# Montana register map
Vendor: ONSemiconductor; Series: Montana Series; File version: 1.0
CPU: CM33 r0p4, little endian, MPU, FPU, 3 interrupt priority bits
Registers are 32-bit, read-write, reset 0x0 unless marked. A register's access mark holds for its fields unless they carry their own. Offsets are from the block's base; [hi:lo] are bit positions; {n}, {i} and the like mark numbered series.

## NVIC — Nested Vector Interrupt Controller
Base 0xE000E100
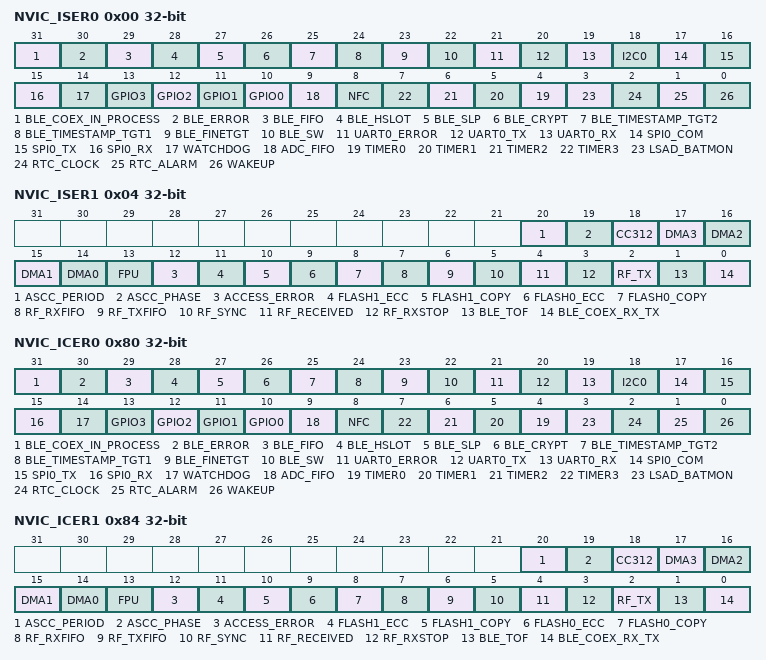
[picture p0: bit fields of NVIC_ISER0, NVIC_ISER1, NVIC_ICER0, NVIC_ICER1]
0x00 NVIC_ISER0 — NVIC External Interrupt Set Enable Register 0
  [31] BLE_COEX_IN_PROCESS — BLE_COEX_IN_PROCESS interrupt set enable
    1=NVIC_BLE_COEX_IN_PROCESS_INT_ENABLE (Enable the BLE_COEX_IN_PROCESS interrupt)
  [30] BLE_ERROR — BLE_ERROR interrupt set enable
    1=NVIC_BLE_ERROR_INT_ENABLE (Enable the BLE_ERROR interrupt)
  [29] BLE_FIFO — BLE_FIFO interrupt set enable
    1=NVIC_BLE_FIFO_INT_ENABLE (Enable the BLE_FIFO interrupt)
  [28] BLE_HSLOT — BLE_HSLOT interrupt set enable
    1=NVIC_BLE_HSLOT_INT_ENABLE (Enable the BLE_HSLOT interrupt)
  [27] BLE_SLP — BLE_SLP interrupt set enable
    1=NVIC_BLE_SLP_INT_ENABLE (Enable the BLE_SLP interrupt)
  [26] BLE_CRYPT — BLE_CRYPT interrupt set enable
    1=NVIC_BLE_CRYPT_INT_ENABLE (Enable the BLE_CRYPT interrupt)
  [25] BLE_TIMESTAMP_TGT2 — BLE_TIMESTAMP_TGT2 interrupt set enable
    1=NVIC_BLE_TIMESTAMP_TGT2_INT_ENABLE (Enable the BLE_TIMESTAMP_TGT2 interrupt)
  [24] BLE_TIMESTAMP_TGT1 — BLE_TIMESTAMP_TGT1 interrupt set enable
    1=NVIC_BLE_TIMESTAMP_TGT1_INT_ENABLE (Enable the BLE_TIMESTAMP_TGT1 interrupt)
  [23] BLE_FINETGT — BLE_FINETGT interrupt set enable
    1=NVIC_BLE_FINETGT_INT_ENABLE (Enable the BLE_FINETGT interrupt)
  [22] BLE_SW — BLE_SW interrupt set enable
    1=NVIC_BLE_SW_INT_ENABLE (Enable the BLE_SW interrupt)
  [21] UART0_ERROR — UART0_ERROR interrupt set enable
    1=NVIC_UART0_ERROR_INT_ENABLE (Enable the UART0_ERROR interrupt)
  [20] UART0_TX — UART0_TX interrupt set enable
    1=NVIC_UART0_TX_INT_ENABLE (Enable the UART0_TX interrupt)
  [19] UART0_RX — UART0_RX interrupt set enable
    1=NVIC_UART0_RX_INT_ENABLE (Enable the UART0_RX interrupt)
  [18] I2C0 — I2C0 interrupt set enable
    1=NVIC_I2C0_INT_ENABLE (Enable the I2C0 interrupt)
  [17] SPI0_COM — SPI0_COM interrupt set enable
    1=NVIC_SPI0_COM_INT_ENABLE (Enable the SPI0_COM interrupt)
  [16] SPI0_TX — SPI0_TX interrupt set enable
    1=NVIC_SPI0_TX_INT_ENABLE (Enable the SPI0_TX interrupt)
  [15] SPI0_RX — SPI0_RX interrupt set enable
    1=NVIC_SPI0_RX_INT_ENABLE (Enable the SPI0_RX interrupt)
  [14] WATCHDOG — WATCHDOG interrupt set enable
    1=NVIC_WATCHDOG_INT_ENABLE (Enable the WATCHDOG interrupt)
  [n+10] GPIO{n} (n=0..3) — GPIO{n} interrupt set enable
    1=NVIC_GPIO{n}_INT_ENABLE (Enable the GPIO{n} interrupt)
  [9] ADC_FIFO — ADC_FIFO interrupt set enable
    1=NVIC_ADC_FIFO_INT_ENABLE (Enable the ADC_FIFO interrupt)
  [8] NFC — NFC interrupt set enable
    1=NVIC_NFC_INT_ENABLE (Enable the NFC interrupt)
  [n+4] TIMER{n} (n=0..3) — TIMER{n} interrupt set enable
    1=NVIC_TIMER{n}_INT_ENABLE (Enable the TIMER{n} interrupt)
  [3] LSAD_BATMON — LSAD_BATMON interrupt set enable
    1=NVIC_LSAD_BATMON_INT_ENABLE (Enable the LSAD_BATMON interrupt)
  [2] RTC_CLOCK — RTC_CLOCK interrupt set enable
    1=NVIC_RTC_CLOCK_INT_ENABLE (Enable the RTC_CLOCK interrupt)
  [1] RTC_ALARM — RTC_ALARM interrupt set enable
    1=NVIC_RTC_ALARM_INT_ENABLE (Enable the RTC_ALARM interrupt)
  [0] WAKEUP — WAKEUP interrupt set enable
    1=NVIC_WAKEUP_INT_ENABLE (Enable the WAKEUP interrupt)
0x04 NVIC_ISER1 — NVIC External Interrupt Set Enable Register 1
  [20] ASCC_PERIOD — ASCC_PERIOD interrupt set enable
    1=NVIC_ASCC_PERIOD_INT_ENABLE (Enable the ASCC_PERIOD interrupt)
  [19] ASCC_PHASE — ASCC_PHASE interrupt set enable
    1=NVIC_ASCC_PHASE_INT_ENABLE (Enable the ASCC_PHASE interrupt)
  [18] CC312 — CC312 interrupt set enable
    1=NVIC_CC312_INT_ENABLE (Enable the CC312 interrupt)
  [n+14] DMA{n} (n=0..3) — DMA{n} interrupt set enable
    1=NVIC_DMA{n}_INT_ENABLE (Enable the DMA{n} interrupt)
  [13] FPU — FPU interrupt set enable
    1=NVIC_FPU_INT_ENABLE (Enable the FPU interrupt)
  [12] ACCESS_ERROR — ACCESS_ERROR interrupt set enable
    1=NVIC_ACCESS_ERROR_INT_ENABLE (Enable the ACCESS_ERROR interrupt)
  [11] FLASH1_ECC — FLASH1_ECC interrupt set enable
    1=NVIC_FLASH1_ECC_INT_ENABLE (Enable the FLASH1_ECC interrupt)
  [10] FLASH1_COPY — FLASH1_COPY interrupt set enable
    1=NVIC_FLASH1_COPY_INT_ENABLE (Enable the FLASH1_COPY interrupt)
  [9] FLASH0_ECC — FLASH0_ECC interrupt set enable
    1=NVIC_FLASH0_ECC_INT_ENABLE (Enable the FLASH0_ECC interrupt)
  [8] FLASH0_COPY — FLASH0_COPY interrupt set enable
    1=NVIC_FLASH0_COPY_INT_ENABLE (Enable the FLASH0_COPY interrupt)
  [7] RF_RXFIFO — RF_RXFIFO interrupt set enable
    1=NVIC_RF_RXFIFO_INT_ENABLE (Enable the RF_RXFIFO interrupt)
  [6] RF_TXFIFO — RF_TXFIFO interrupt set enable
    1=NVIC_RF_TXFIFO_INT_ENABLE (Enable the RF_TXFIFO interrupt)
  [5] RF_SYNC — RF_SYNC interrupt set enable
    1=NVIC_RF_SYNC_INT_ENABLE (Enable the RF_SYNC interrupt)
  [4] RF_RECEIVED — RF_RECEIVED interrupt set enable
    1=NVIC_RF_RECEIVED_INT_ENABLE (Enable the RF_RECEIVED interrupt)
  [3] RF_RXSTOP — RF_RXSTOP interrupt set enable
    1=NVIC_RF_RXSTOP_INT_ENABLE (Enable the RF_RXSTOP interrupt)
  [2] RF_TX — RF_TX interrupt set enable
    1=NVIC_RF_TX_INT_ENABLE (Enable the RF_TX interrupt)
  [1] BLE_TOF — BLE_TOF interrupt set enable
    1=NVIC_BLE_TOF_INT_ENABLE (Enable the BLE_TOF interrupt)
  [0] BLE_COEX_RX_TX — BLE_COEX_RX_TX interrupt set enable
    1=NVIC_BLE_COEX_RX_TX_INT_ENABLE (Enable the BLE_COEX_RX_TX interrupt)
0x80 NVIC_ICER0 — NVIC External Interrupt Clear Enable Register 0
  [31] BLE_COEX_IN_PROCESS — BLE_COEX_IN_PROCESS interrupt clear enable
    1=NVIC_BLE_COEX_IN_PROCESS_INT_DISABLE (Disable the BLE_COEX_IN_PROCESS interrupt)
  [30] BLE_ERROR — BLE_ERROR interrupt clear enable
    1=NVIC_BLE_ERROR_INT_DISABLE (Disable the BLE_ERROR interrupt)
  [29] BLE_FIFO — BLE_FIFO interrupt clear enable
    1=NVIC_BLE_FIFO_INT_DISABLE (Disable the BLE_FIFO interrupt)
  [28] BLE_HSLOT — BLE_HSLOT interrupt clear enable
    1=NVIC_BLE_HSLOT_INT_DISABLE (Disable the BLE_HSLOT interrupt)
  [27] BLE_SLP — BLE_SLP interrupt clear enable
    1=NVIC_BLE_SLP_INT_DISABLE (Disable the BLE_SLP interrupt)
  [26] BLE_CRYPT — BLE_CRYPT interrupt clear enable
    1=NVIC_BLE_CRYPT_INT_DISABLE (Disable the BLE_CRYPT interrupt)
  [25] BLE_TIMESTAMP_TGT2 — BLE_TIMESTAMP_TGT2 interrupt clear enable
    1=NVIC_BLE_TIMESTAMP_TGT2_INT_DISABLE (Disable the BLE_TIMESTAMP_TGT2 interrupt)
  [24] BLE_TIMESTAMP_TGT1 — BLE_TIMESTAMP_TGT1 interrupt clear enable
    1=NVIC_BLE_TIMESTAMP_TGT1_INT_DISABLE (Disable the BLE_TIMESTAMP_TGT1 interrupt)
  [23] BLE_FINETGT — BLE_FINETGT interrupt clear enable
    1=NVIC_BLE_FINETGT_INT_DISABLE (Disable the BLE_FINETGT interrupt)
  [22] BLE_SW — BLE_SW interrupt clear enable
    1=NVIC_BLE_SW_INT_DISABLE (Disable the BLE_SW interrupt)
  [21] UART0_ERROR — UART0_ERROR interrupt clear enable
    1=NVIC_UART0_ERROR_INT_DISABLE (Disable the UART0_ERROR interrupt)
  [20] UART0_TX — UART0_TX interrupt clear enable
    1=NVIC_UART0_TX_INT_DISABLE (Disable the UART0_TX interrupt)
  [19] UART0_RX — UART0_RX interrupt clear enable
    1=NVIC_UART0_RX_INT_DISABLE (Disable the UART0_RX interrupt)
  [18] I2C0 — I2C0 interrupt clear enable
    1=NVIC_I2C0_INT_DISABLE (Disable the I2C0 interrupt)
  [17] SPI0_COM — SPI0_COM interrupt clear enable
    1=NVIC_SPI0_COM_INT_DISABLE (Disable the SPI0_COM interrupt)
  [16] SPI0_TX — SPI0_TX interrupt clear enable
    1=NVIC_SPI0_TX_INT_DISABLE (Disable the SPI0_TX interrupt)
  [15] SPI0_RX — SPI0_RX interrupt clear enable
    1=NVIC_SPI0_RX_INT_DISABLE (Disable the SPI0_RX interrupt)
  [14] WATCHDOG — WATCHDOG interrupt clear enable
    1=NVIC_WATCHDOG_INT_DISABLE (Disable the WATCHDOG interrupt)
  [n+10] GPIO{n} (n=0..3) — GPIO{n} interrupt clear enable
    1=NVIC_GPIO{n}_INT_DISABLE (Disable the GPIO{n} interrupt)
  [9] ADC_FIFO — ADC_FIFO interrupt clear enable
    1=NVIC_ADC_FIFO_INT_DISABLE (Disable the ADC_FIFO interrupt)
  [8] NFC — NFC interrupt clear enable
    1=NVIC_NFC_INT_DISABLE (Disable the NFC interrupt)
  [n+4] TIMER{n} (n=0..3) — TIMER{n} interrupt clear enable
    1=NVIC_TIMER{n}_INT_DISABLE (Disable the TIMER{n} interrupt)
  [3] LSAD_BATMON — LSAD_BATMON interrupt clear enable
    1=NVIC_LSAD_BATMON_INT_DISABLE (Disable the LSAD_BATMON interrupt)
  [2] RTC_CLOCK — RTC_CLOCK interrupt clear enable
    1=NVIC_RTC_CLOCK_INT_DISABLE (Disable the RTC_CLOCK interrupt)
  [1] RTC_ALARM — RTC_ALARM interrupt clear enable
    1=NVIC_RTC_ALARM_INT_DISABLE (Disable the RTC_ALARM interrupt)
  [0] WAKEUP — WAKEUP interrupt clear enable
    1=NVIC_WAKEUP_INT_DISABLE (Disable the WAKEUP interrupt)
0x84 NVIC_ICER1 — NVIC External Interrupt Clear Enable Register 1
  [20] ASCC_PERIOD — ASCC_PERIOD interrupt clear enable
    1=NVIC_ASCC_PERIOD_INT_DISABLE (Disable the ASCC_PERIOD interrupt)
  [19] ASCC_PHASE — ASCC_PHASE interrupt clear enable
    1=NVIC_ASCC_PHASE_INT_DISABLE (Disable the ASCC_PHASE interrupt)
  [18] CC312 — CC312 interrupt clear enable
    1=NVIC_CC312_INT_DISABLE (Disable the CC312 interrupt)
  [n+14] DMA{n} (n=0..3) — DMA{n} interrupt clear enable
    1=NVIC_DMA{n}_INT_DISABLE (Disable the DMA{n} interrupt)
  [13] FPU — FPU interrupt clear enable
    1=NVIC_FPU_INT_DISABLE (Disable the FPU interrupt)
  [12] ACCESS_ERROR — ACCESS_ERROR interrupt clear enable
    1=NVIC_ACCESS_ERROR_INT_DISABLE (Disable the ACCESS_ERROR interrupt)
  [11] FLASH1_ECC — FLASH1_ECC interrupt clear enable
    1=NVIC_FLASH1_ECC_INT_DISABLE (Disable the FLASH1_ECC interrupt)
  [10] FLASH1_COPY — FLASH1_COPY interrupt clear enable
    1=NVIC_FLASH1_COPY_INT_DISABLE (Disable the FLASH1_COPY interrupt)
  [9] FLASH0_ECC — FLASH0_ECC interrupt clear enable
    1=NVIC_FLASH0_ECC_INT_DISABLE (Disable the FLASH0_ECC interrupt)
  [8] FLASH0_COPY — FLASH0_COPY interrupt clear enable
    1=NVIC_FLASH0_COPY_INT_DISABLE (Disable the FLASH0_COPY interrupt)
  [7] RF_RXFIFO — RF_RXFIFO interrupt clear enable
    1=NVIC_RF_RXFIFO_INT_DISABLE (Disable the RF_RXFIFO interrupt)
  [6] RF_TXFIFO — RF_TXFIFO interrupt clear enable
    1=NVIC_RF_TXFIFO_INT_DISABLE (Disable the RF_TXFIFO interrupt)
  [5] RF_SYNC — RF_SYNC interrupt clear enable
    1=NVIC_RF_SYNC_INT_DISABLE (Disable the RF_SYNC interrupt)
  [4] RF_RECEIVED — RF_RECEIVED interrupt clear enable
    1=NVIC_RF_RECEIVED_INT_DISABLE (Disable the RF_RECEIVED interrupt)
  [3] RF_RXSTOP — RF_RXSTOP interrupt clear enable
    1=NVIC_RF_RXSTOP_INT_DISABLE (Disable the RF_RXSTOP interrupt)
  [2] RF_TX — RF_TX interrupt clear enable
    1=NVIC_RF_TX_INT_DISABLE (Disable the RF_TX interrupt)
  [1] BLE_TOF — BLE_TOF interrupt clear enable
    1=NVIC_BLE_TOF_INT_DISABLE (Disable the BLE_TOF interrupt)
  [0] BLE_COEX_RX_TX — BLE_COEX_RX_TX interrupt clear enable
    1=NVIC_BLE_COEX_RX_TX_INT_DISABLE (Disable the BLE_COEX_RX_TX interrupt)
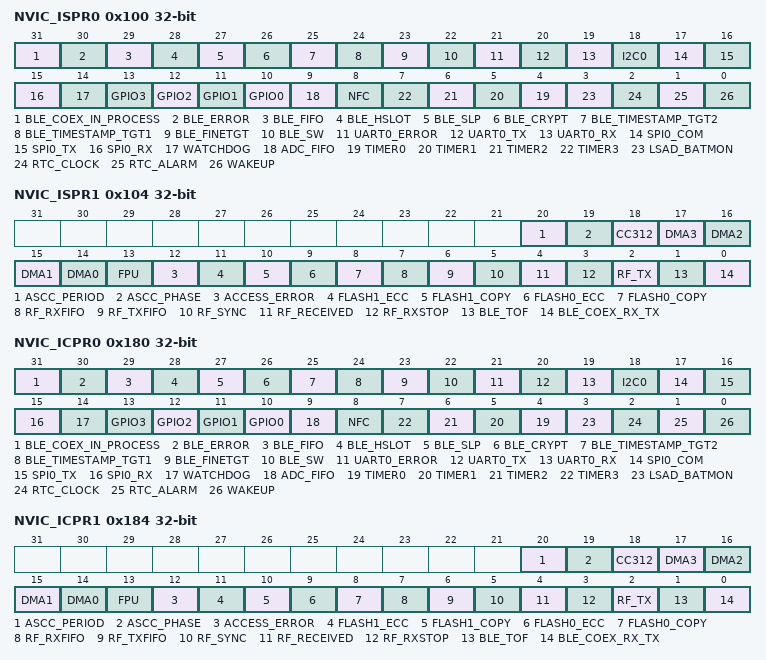
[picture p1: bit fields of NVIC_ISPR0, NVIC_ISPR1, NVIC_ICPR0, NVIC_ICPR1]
0x100 NVIC_ISPR0 — NVIC External Interrupt Set Pending Register 0
  [31] BLE_COEX_IN_PROCESS — BLE_COEX_IN_PROCESS interrupt set pending
    1=NVIC_BLE_COEX_IN_PROCESS_INT_SETPEND (Set the BLE_COEX_IN_PROCESS interrupt pending)
  [30] BLE_ERROR — BLE_ERROR interrupt set pending
    1=NVIC_BLE_ERROR_INT_SETPEND (Set the BLE_ERROR interrupt pending)
  [29] BLE_FIFO — BLE_FIFO interrupt set pending
    1=NVIC_BLE_FIFO_INT_SETPEND (Set the BLE_FIFO interrupt pending)
  [28] BLE_HSLOT — BLE_HSLOT interrupt set pending
    1=NVIC_BLE_HSLOT_INT_SETPEND (Set the BLE_HSLOT interrupt pending)
  [27] BLE_SLP — BLE_SLP interrupt set pending
    1=NVIC_BLE_SLP_INT_SETPEND (Set the BLE_SLP interrupt pending)
  [26] BLE_CRYPT — BLE_CRYPT interrupt set pending
    1=NVIC_BLE_CRYPT_INT_SETPEND (Set the BLE_CRYPT interrupt pending)
  [25] BLE_TIMESTAMP_TGT2 — BLE_TIMESTAMP_TGT2 interrupt set pending
    1=NVIC_BLE_TIMESTAMP_TGT2_INT_SETPEND (Set the BLE_TIMESTAMP_TGT2 interrupt pending)
  [24] BLE_TIMESTAMP_TGT1 — BLE_TIMESTAMP_TGT1 interrupt set pending
    1=NVIC_BLE_TIMESTAMP_TGT1_INT_SETPEND (Set the BLE_TIMESTAMP_TGT1 interrupt pending)
  [23] BLE_FINETGT — BLE_FINETGT interrupt set pending
    1=NVIC_BLE_FINETGT_INT_SETPEND (Set the BLE_FINETGT interrupt pending)
  [22] BLE_SW — BLE_SW interrupt set pending
    1=NVIC_BLE_SW_INT_SETPEND (Set the BLE_SW interrupt pending)
  [21] UART0_ERROR — UART0_ERROR interrupt set pending
    1=NVIC_UART0_ERROR_INT_SETPEND (Set the UART0_ERROR interrupt pending)
  [20] UART0_TX — UART0_TX interrupt set pending
    1=NVIC_UART0_TX_INT_SETPEND (Set the UART0_TX interrupt pending)
  [19] UART0_RX — UART0_RX interrupt set pending
    1=NVIC_UART0_RX_INT_SETPEND (Set the UART0_RX interrupt pending)
  [18] I2C0 — I2C0 interrupt set pending
    1=NVIC_I2C0_INT_SETPEND (Set the I2C0 interrupt pending)
  [17] SPI0_COM — SPI0_COM interrupt set pending
    1=NVIC_SPI0_COM_INT_SETPEND (Set the SPI0_COM interrupt pending)
  [16] SPI0_TX — SPI0_TX interrupt set pending
    1=NVIC_SPI0_TX_INT_SETPEND (Set the SPI0_TX interrupt pending)
  [15] SPI0_RX — SPI0_RX interrupt set pending
    1=NVIC_SPI0_RX_INT_SETPEND (Set the SPI0_RX interrupt pending)
  [14] WATCHDOG — WATCHDOG interrupt set pending
    1=NVIC_WATCHDOG_INT_SETPEND (Set the WATCHDOG interrupt pending)
  [n+10] GPIO{n} (n=0..3) — GPIO{n} interrupt set pending
    1=NVIC_GPIO{n}_INT_SETPEND (Set the GPIO{n} interrupt pending)
  [9] ADC_FIFO — ADC_FIFO interrupt set pending
    1=NVIC_ADC_FIFO_INT_SETPEND (Set the ADC_FIFO interrupt pending)
  [8] NFC — NFC interrupt set pending
    1=NVIC_NFC_INT_SETPEND (Set the NFC interrupt pending)
  [n+4] TIMER{n} (n=0..3) — TIMER{n} interrupt set pending
    1=NVIC_TIMER{n}_INT_SETPEND (Set the TIMER{n} interrupt pending)
  [3] LSAD_BATMON — LSAD_BATMON interrupt set pending
    1=NVIC_LSAD_BATMON_INT_SETPEND (Set the LSAD_BATMON interrupt pending)
  [2] RTC_CLOCK — RTC_CLOCK interrupt set pending
    1=NVIC_RTC_CLOCK_INT_SETPEND (Set the RTC_CLOCK interrupt pending)
  [1] RTC_ALARM — RTC_ALARM interrupt set pending
    1=NVIC_RTC_ALARM_INT_SETPEND (Set the RTC_ALARM interrupt pending)
  [0] WAKEUP — WAKEUP interrupt set pending
    1=NVIC_WAKEUP_INT_SETPEND (Set the WAKEUP interrupt pending)
0x104 NVIC_ISPR1 — NVIC External Interrupt Set Pending Register 1
  [20] ASCC_PERIOD — ASCC_PERIOD interrupt set pending
    1=NVIC_ASCC_PERIOD_INT_SETPEND (Set the ASCC_PERIOD interrupt pending)
  [19] ASCC_PHASE — ASCC_PHASE interrupt set pending
    1=NVIC_ASCC_PHASE_INT_SETPEND (Set the ASCC_PHASE interrupt pending)
  [18] CC312 — CC312 interrupt set pending
    1=NVIC_CC312_INT_SETPEND (Set the CC312 interrupt pending)
  [n+14] DMA{n} (n=0..3) — DMA{n} interrupt set pending
    1=NVIC_DMA{n}_INT_SETPEND (Set the DMA{n} interrupt pending)
  [13] FPU — FPU interrupt set pending
    1=NVIC_FPU_INT_SETPEND (Set the FPU interrupt pending)
  [12] ACCESS_ERROR — ACCESS_ERROR interrupt set pending
    1=NVIC_ACCESS_ERROR_INT_SETPEND (Set the ACCESS_ERROR interrupt pending)
  [11] FLASH1_ECC — FLASH1_ECC interrupt set pending
    1=NVIC_FLASH1_ECC_INT_SETPEND (Set the FLASH1_ECC interrupt pending)
  [10] FLASH1_COPY — FLASH1_COPY interrupt set pending
    1=NVIC_FLASH1_COPY_INT_SETPEND (Set the FLASH1_COPY interrupt pending)
  [9] FLASH0_ECC — FLASH0_ECC interrupt set pending
    1=NVIC_FLASH0_ECC_INT_SETPEND (Set the FLASH0_ECC interrupt pending)
  [8] FLASH0_COPY — FLASH0_COPY interrupt set pending
    1=NVIC_FLASH0_COPY_INT_SETPEND (Set the FLASH0_COPY interrupt pending)
  [7] RF_RXFIFO — RF_RXFIFO interrupt set pending
    1=NVIC_RF_RXFIFO_INT_SETPEND (Set the RF_RXFIFO interrupt pending)
  [6] RF_TXFIFO — RF_TXFIFO interrupt set pending
    1=NVIC_RF_TXFIFO_INT_SETPEND (Set the RF_TXFIFO interrupt pending)
  [5] RF_SYNC — RF_SYNC interrupt set pending
    1=NVIC_RF_SYNC_INT_SETPEND (Set the RF_SYNC interrupt pending)
  [4] RF_RECEIVED — RF_RECEIVED interrupt set pending
    1=NVIC_RF_RECEIVED_INT_SETPEND (Set the RF_RECEIVED interrupt pending)
  [3] RF_RXSTOP — RF_RXSTOP interrupt set pending
    1=NVIC_RF_RXSTOP_INT_SETPEND (Set the RF_RXSTOP interrupt pending)
  [2] RF_TX — RF_TX interrupt set pending
    1=NVIC_RF_TX_INT_SETPEND (Set the RF_TX interrupt pending)
  [1] BLE_TOF — BLE_TOF interrupt set pending
    1=NVIC_BLE_TOF_INT_SETPEND (Set the BLE_TOF interrupt pending)
  [0] BLE_COEX_RX_TX — BLE_COEX_RX_TX interrupt set pending
    1=NVIC_BLE_COEX_RX_TX_INT_SETPEND (Set the BLE_COEX_RX_TX interrupt pending)
0x180 NVIC_ICPR0 — NVIC External Interrupt Clear Pending Register 0
  [31] BLE_COEX_IN_PROCESS — BLE_COEX_IN_PROCESS interrupt clear pending
    1=NVIC_BLE_COEX_IN_PROCESS_INT_CLRPEND (Clear the NVIC_BLE_COEX_IN_PROCESS_INT_CLRPEND interrupt status bit)
  [30] BLE_ERROR — BLE_ERROR interrupt clear pending
    1=NVIC_BLE_ERROR_INT_CLRPEND (Clear the NVIC_BLE_ERROR_INT_CLRPEND interrupt status bit)
  [29] BLE_FIFO — BLE_FIFO interrupt clear pending
    1=NVIC_BLE_FIFO_INT_CLRPEND (Clear the NVIC_BLE_FIFO_INT_CLRPEND interrupt status bit)
  [28] BLE_HSLOT — BLE_HSLOT interrupt clear pending
    1=NVIC_BLE_HSLOT_INT_CLRPEND (Clear the NVIC_BLE_HSLOT_INT_CLRPEND interrupt status bit)
  [27] BLE_SLP — BLE_SLP interrupt clear pending
    1=NVIC_BLE_SLP_INT_CLRPEND (Clear the NVIC_BLE_SLP_INT_CLRPEND interrupt status bit)
  [26] BLE_CRYPT — BLE_CRYPT interrupt clear pending
    1=NVIC_BLE_CRYPT_INT_CLRPEND (Clear the NVIC_BLE_CRYPT_INT_CLRPEND interrupt status bit)
  [25] BLE_TIMESTAMP_TGT2 — BLE_TIMESTAMP_TGT2 interrupt clear pending
    1=NVIC_BLE_TIMESTAMP_TGT2_INT_CLRPEND (Clear the NVIC_BLE_TIMESTAMP_TGT2_INT_CLRPEND interrupt status bit)
  [24] BLE_TIMESTAMP_TGT1 — BLE_TIMESTAMP_TGT1 interrupt clear pending
    1=NVIC_BLE_TIMESTAMP_TGT1_INT_CLRPEND (Clear the NVIC_BLE_TIMESTAMP_TGT1_INT_CLRPEND interrupt status bit)
  [23] BLE_FINETGT — BLE_FINETGT interrupt clear pending
    1=NVIC_BLE_FINETGT_INT_CLRPEND (Clear the NVIC_BLE_FINETGT_INT_CLRPEND interrupt status bit)
  [22] BLE_SW — BLE_SW interrupt clear pending
    1=NVIC_BLE_SW_INT_CLRPEND (Clear the NVIC_BLE_SW_INT_CLRPEND interrupt status bit)
  [21] UART0_ERROR — UART0_ERROR interrupt clear pending
    1=NVIC_UART0_ERROR_INT_CLRPEND (Clear the NVIC_UART0_ERROR_INT_CLRPEND interrupt status bit)
  [20] UART0_TX — UART0_TX interrupt clear pending
    1=NVIC_UART0_TX_INT_CLRPEND (Clear the NVIC_UART0_TX_INT_CLRPEND interrupt status bit)
  [19] UART0_RX — UART0_RX interrupt clear pending
    1=NVIC_UART0_RX_INT_CLRPEND (Clear the NVIC_UART0_RX_INT_CLRPEND interrupt status bit)
  [18] I2C0 — I2C0 interrupt clear pending
    1=NVIC_I2C0_INT_CLRPEND (Clear the NVIC_I2C0_INT_CLRPEND interrupt status bit)
  [17] SPI0_COM — SPI0_COM interrupt clear pending
    1=NVIC_SPI0_COM_INT_CLRPEND (Clear the NVIC_SPI0_COM_INT_CLRPEND interrupt status bit)
  [16] SPI0_TX — SPI0_TX interrupt clear pending
    1=NVIC_SPI0_TX_INT_CLRPEND (Clear the NVIC_SPI0_TX_INT_CLRPEND interrupt status bit)
  [15] SPI0_RX — SPI0_RX interrupt clear pending
    1=NVIC_SPI0_RX_INT_CLRPEND (Clear the NVIC_SPI0_RX_INT_CLRPEND interrupt status bit)
  [14] WATCHDOG — WATCHDOG interrupt clear pending
    1=NVIC_WATCHDOG_INT_CLRPEND (Clear the NVIC_WATCHDOG_INT_CLRPEND interrupt status bit)
  [n+10] GPIO{n} (n=0..3) — GPIO{n} interrupt clear pending
    1=NVIC_GPIO{n}_INT_CLRPEND (Clear the NVIC_GPIO{n}_INT_CLRPEND interrupt status bit)
  [9] ADC_FIFO — ADC_FIFO interrupt clear pending
    1=NVIC_ADC_FIFO_INT_CLRPEND (Clear the NVIC_ADC_FIFO_INT_CLRPEND interrupt status bit)
  [8] NFC — NFC interrupt clear pending
    1=NVIC_NFC_INT_CLRPEND (Clear the NVIC_NFC_INT_CLRPEND interrupt status bit)
  [n+4] TIMER{n} (n=0..3) — TIMER{n} interrupt clear pending
    1=NVIC_TIMER{n}_INT_CLRPEND (Clear the NVIC_TIMER{n}_INT_CLRPEND interrupt status bit)
  [3] LSAD_BATMON — LSAD_BATMON interrupt clear pending
    1=NVIC_LSAD_BATMON_INT_CLRPEND (Clear the NVIC_LSAD_BATMON_INT_CLRPEND interrupt status bit)
  [2] RTC_CLOCK — RTC_CLOCK interrupt clear pending
    1=NVIC_RTC_CLOCK_INT_CLRPEND (Clear the NVIC_RTC_CLOCK_INT_CLRPEND interrupt status bit)
  [1] RTC_ALARM — RTC_ALARM interrupt clear pending
    1=NVIC_RTC_ALARM_INT_CLRPEND (Clear the NVIC_RTC_ALARM_INT_CLRPEND interrupt status bit)
  [0] WAKEUP — WAKEUP interrupt clear pending
    1=NVIC_WAKEUP_INT_CLRPEND (Clear the NVIC_WAKEUP_INT_CLRPEND interrupt status bit)
0x184 NVIC_ICPR1 — NVIC External Interrupt Clear Pending Register 1
  [20] ASCC_PERIOD — ASCC_PERIOD interrupt clear pending
    1=NVIC_ASCC_PERIOD_INT_CLRPEND (Clear the NVIC_ASCC_PERIOD_INT_CLRPEND interrupt status bit)
  [19] ASCC_PHASE — ASCC_PHASE interrupt clear pending
    1=NVIC_ASCC_PHASE_INT_CLRPEND (Clear the NVIC_ASCC_PHASE_INT_CLRPEND interrupt status bit)
  [18] CC312 — CC312 interrupt clear pending
    1=NVIC_CC312_INT_CLRPEND (Clear the NVIC_CC312_INT_CLRPEND interrupt status bit)
  [n+14] DMA{n} (n=0..3) — DMA{n} interrupt clear pending
    1=NVIC_DMA{n}_INT_CLRPEND (Clear the NVIC_DMA{n}_INT_CLRPEND interrupt status bit)
  [13] FPU — FPU interrupt clear pending
    1=NVIC_FPU_INT_CLRPEND (Clear the NVIC_FPU_INT_CLRPEND interrupt status bit)
  [12] ACCESS_ERROR — ACCESS_ERROR interrupt clear pending
    1=NVIC_ACCESS_ERROR_INT_CLRPEND (Clear the NVIC_ACCESS_ERROR_INT_CLRPEND interrupt status bit)
  [11] FLASH1_ECC — FLASH1_ECC interrupt clear pending
    1=NVIC_FLASH1_ECC_INT_CLRPEND (Clear the NVIC_FLASH1_ECC_INT_CLRPEND interrupt status bit)
  [10] FLASH1_COPY — FLASH1_COPY interrupt clear pending
    1=NVIC_FLASH1_COPY_INT_CLRPEND (Clear the NVIC_FLASH1_COPY_INT_CLRPEND interrupt status bit)
  [9] FLASH0_ECC — FLASH0_ECC interrupt clear pending
    1=NVIC_FLASH0_ECC_INT_CLRPEND (Clear the NVIC_FLASH0_ECC_INT_CLRPEND interrupt status bit)
  [8] FLASH0_COPY — FLASH0_COPY interrupt clear pending
    1=NVIC_FLASH0_COPY_INT_CLRPEND (Clear the NVIC_FLASH0_COPY_INT_CLRPEND interrupt status bit)
  [7] RF_RXFIFO — RF_RXFIFO interrupt clear pending
    1=NVIC_RF_RXFIFO_INT_CLRPEND (Clear the NVIC_RF_RXFIFO_INT_CLRPEND interrupt status bit)
  [6] RF_TXFIFO — RF_TXFIFO interrupt clear pending
    1=NVIC_RF_TXFIFO_INT_CLRPEND (Clear the NVIC_RF_TXFIFO_INT_CLRPEND interrupt status bit)
  [5] RF_SYNC — RF_SYNC interrupt clear pending
    1=NVIC_RF_SYNC_INT_CLRPEND (Clear the NVIC_RF_SYNC_INT_CLRPEND interrupt status bit)
  [4] RF_RECEIVED — RF_RECEIVED interrupt clear pending
    1=NVIC_RF_RECEIVED_INT_CLRPEND (Clear the NVIC_RF_RECEIVED_INT_CLRPEND interrupt status bit)
  [3] RF_RXSTOP — RF_RXSTOP interrupt clear pending
    1=NVIC_RF_RXSTOP_INT_CLRPEND (Clear the NVIC_RF_RXSTOP_INT_CLRPEND interrupt status bit)
  [2] RF_TX — RF_TX interrupt clear pending
    1=NVIC_RF_TX_INT_CLRPEND (Clear the NVIC_RF_TX_INT_CLRPEND interrupt status bit)
  [1] BLE_TOF — BLE_TOF interrupt clear pending
    1=NVIC_BLE_TOF_INT_CLRPEND (Clear the NVIC_BLE_TOF_INT_CLRPEND interrupt status bit)
  [0] BLE_COEX_RX_TX — BLE_COEX_RX_TX interrupt clear pending
    1=NVIC_BLE_COEX_RX_TX_INT_CLRPEND (Clear the NVIC_BLE_COEX_RX_TX_INT_CLRPEND interrupt status bit)
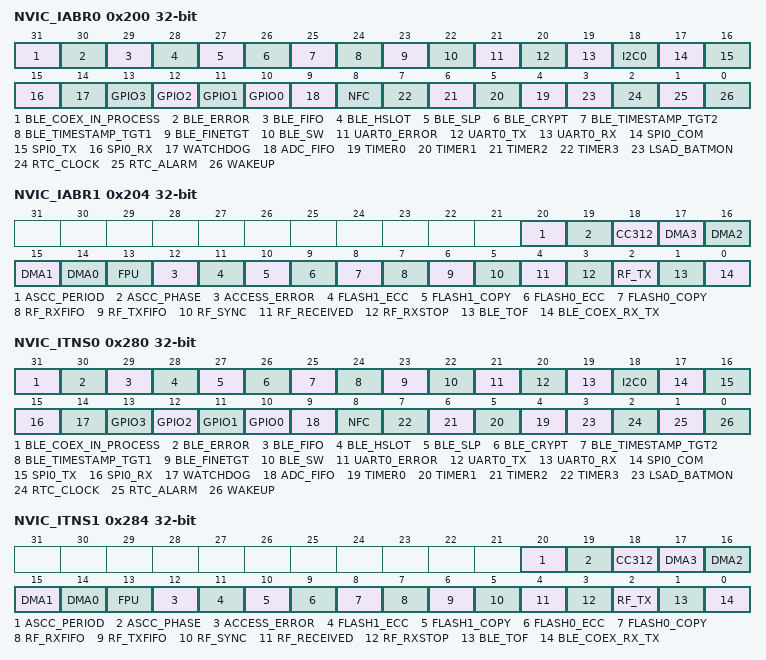
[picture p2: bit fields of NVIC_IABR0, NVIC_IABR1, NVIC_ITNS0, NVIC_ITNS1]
0x200 NVIC_IABR0 ro — NVIC External Interrupt Active Register 0
  [31] BLE_COEX_IN_PROCESS — Set the BLE_COEX_IN_PROCESS interrupt as non-secure
    1=NVIC_BLE_COEX_IN_PROCESS_INT_ACTIVE (The NVIC_BLE_COEX_IN_PROCESS_INT_ACTIVE interrupt is active)
  [30] BLE_ERROR — Set the BLE_ERROR interrupt as active
    1=NVIC_BLE_ERROR_INT_ACTIVE (The NVIC_BLE_ERROR_INT_ACTIVE interrupt is active)
  [29] BLE_FIFO — Set the BLE_FIFO interrupt as active
    1=NVIC_BLE_FIFO_INT_ACTIVE (The NVIC_BLE_FIFO_INT_ACTIVE interrupt is active)
  [28] BLE_HSLOT — Set the BLE_HSLOT interrupt as active
    1=NVIC_BLE_HSLOT_INT_ACTIVE (The NVIC_BLE_HSLOT_INT_ACTIVE interrupt is active)
  [27] BLE_SLP — Set the BLE_SLP interrupt as active
    1=NVIC_BLE_SLP_INT_ACTIVE (The NVIC_BLE_SLP_INT_ACTIVE interrupt is active)
  [26] BLE_CRYPT — Set the BLE_CRYPT interrupt as active
    1=NVIC_BLE_CRYPT_INT_ACTIVE (The NVIC_BLE_CRYPT_INT_ACTIVE interrupt is active)
  [25] BLE_TIMESTAMP_TGT2 — Set the BLE_TIMESTAMP_TGT2 interrupt as active
    1=NVIC_BLE_TIMESTAMP_TGT2_INT_ACTIVE (The NVIC_BLE_TIMESTAMP_TGT2_INT_ACTIVE interrupt is active)
  [24] BLE_TIMESTAMP_TGT1 — Set the BLE_TIMESTAMP_TGT1 interrupt as active
    1=NVIC_BLE_TIMESTAMP_TGT1_INT_ACTIVE (The NVIC_BLE_TIMESTAMP_TGT1_INT_ACTIVE interrupt is active)
  [23] BLE_FINETGT — Set the BLE_FINETGT interrupt as active
    1=NVIC_BLE_FINETGT_INT_ACTIVE (The NVIC_BLE_FINETGT_INT_ACTIVE interrupt is active)
  [22] BLE_SW — Set the BLE_SW interrupt as active
    1=NVIC_BLE_SW_INT_ACTIVE (The NVIC_BLE_SW_INT_ACTIVE interrupt is active)
  [21] UART0_ERROR — Set the UART0_ERROR interrupt as active
    1=NVIC_UART0_ERROR_INT_ACTIVE (The NVIC_UART0_ERROR_INT_ACTIVE interrupt is active)
  [20] UART0_TX — Set the UART0_TX interrupt as active
    1=NVIC_UART0_TX_INT_ACTIVE (The NVIC_UART0_TX_INT_ACTIVE interrupt is active)
  [19] UART0_RX — Set the UART0_RX interrupt as active
    1=NVIC_UART0_RX_INT_ACTIVE (The NVIC_UART0_RX_INT_ACTIVE interrupt is active)
  [18] I2C0 — Set the I2C0 interrupt as active
    1=NVIC_I2C0_INT_ACTIVE (The NVIC_I2C0_INT_ACTIVE interrupt is active)
  [17] SPI0_COM — Set the SPI0_COM interrupt as active
    1=NVIC_SPI0_COM_INT_ACTIVE (The NVIC_SPI0_COM_INT_ACTIVE interrupt is active)
  [16] SPI0_TX — Set the SPI0_TX interrupt as active
    1=NVIC_SPI0_TX_INT_ACTIVE (The NVIC_SPI0_TX_INT_ACTIVE interrupt is active)
  [15] SPI0_RX — Set the SPI0_RX interrupt as active
    1=NVIC_SPI0_RX_INT_ACTIVE (The NVIC_SPI0_RX_INT_ACTIVE interrupt is active)
  [14] WATCHDOG — Set the WATCHDOG interrupt as active
    1=NVIC_WATCHDOG_INT_ACTIVE (The NVIC_WATCHDOG_INT_ACTIVE interrupt is active)
  [n+10] GPIO{n} (n=0..3) — Set the GPIO{n} interrupt as active
    1=NVIC_GPIO{n}_INT_ACTIVE (The NVIC_GPIO{n}_INT_ACTIVE interrupt is active)
  [9] ADC_FIFO — Set the ADC_FIFO interrupt as active
    1=NVIC_ADC_FIFO_INT_ACTIVE (The NVIC_ADC_FIFO_INT_ACTIVE interrupt is active)
  [8] NFC — Set the NFC interrupt as active
    1=NVIC_NFC_INT_ACTIVE (The NVIC_NFC_INT_ACTIVE interrupt is active)
  [n+4] TIMER{n} (n=0..3) — Set the TIMER{n} interrupt as active
    1=NVIC_TIMER{n}_INT_ACTIVE (The NVIC_TIMER{n}_INT_ACTIVE interrupt is active)
  [3] LSAD_BATMON — Set the LSAD_BATMON interrupt as active
    1=NVIC_LSAD_BATMON_INT_ACTIVE (The NVIC_LSAD_BATMON_INT_ACTIVE interrupt is active)
  [2] RTC_CLOCK — Set the RTC_CLOCK interrupt as active
    1=NVIC_RTC_CLOCK_INT_ACTIVE (The NVIC_RTC_CLOCK_INT_ACTIVE interrupt is active)
  [1] RTC_ALARM — Set the RTC_ALARM interrupt as active
    1=NVIC_RTC_ALARM_INT_ACTIVE (The NVIC_RTC_ALARM_INT_ACTIVE interrupt is active)
  [0] WAKEUP — Set the WAKEUP interrupt as active
    1=NVIC_WAKEUP_INT_ACTIVE (The NVIC_WAKEUP_INT_ACTIVE interrupt is active)
0x204 NVIC_IABR1 ro — NVIC External Interrupt Active Register 1
  [20] ASCC_PERIOD — Set the ASCC_PERIOD interrupt as active
    1=NVIC_ASCC_PERIOD_INT_ACTIVE (The NVIC_ASCC_PERIOD_INT_ACTIVE interrupt is active)
  [19] ASCC_PHASE — Set the ASCC_PHASE interrupt as active
    1=NVIC_ASCC_PHASE_INT_ACTIVE (The NVIC_ASCC_PHASE_INT_ACTIVE interrupt is active)
  [18] CC312 — Set the CC312 interrupt as active
    1=NVIC_CC312_INT_ACTIVE (The NVIC_CC312_INT_ACTIVE interrupt is active)
  [n+14] DMA{n} (n=0..3) — Set the DMA{n} interrupt as active
    1=NVIC_DMA{n}_INT_ACTIVE (The NVIC_DMA{n}_INT_ACTIVE interrupt is active)
  [13] FPU — Set the FPU interrupt as active
    1=NVIC_FPU_INT_ACTIVE (The NVIC_FPU_INT_ACTIVE interrupt is active)
  [12] ACCESS_ERROR — Set the ACCESS_ERROR interrupt as active
    1=NVIC_ACCESS_ERROR_INT_ACTIVE (The NVIC_ACCESS_ERROR_INT_ACTIVE interrupt is active)
  [11] FLASH1_ECC — Set the FLASH1_ECC interrupt as active
    1=NVIC_FLASH1_ECC_INT_ACTIVE (The NVIC_FLASH1_ECC_INT_ACTIVE interrupt is active)
  [10] FLASH1_COPY — Set the FLASH1_COPY interrupt as active
    1=NVIC_FLASH1_COPY_INT_ACTIVE (The NVIC_FLASH1_COPY_INT_ACTIVE interrupt is active)
  [9] FLASH0_ECC — Set the FLASH0_ECC interrupt as active
    1=NVIC_FLASH0_ECC_INT_ACTIVE (The NVIC_FLASH0_ECC_INT_ACTIVE interrupt is active)
  [8] FLASH0_COPY — Set the FLASH0_COPY interrupt as active
    1=NVIC_FLASH0_COPY_INT_ACTIVE (The NVIC_FLASH0_COPY_INT_ACTIVE interrupt is active)
  [7] RF_RXFIFO — Set the RF_RXFIFO interrupt as active
    1=NVIC_RF_RXFIFO_INT_ACTIVE (The NVIC_RF_RXFIFO_INT_ACTIVE interrupt is active)
  [6] RF_TXFIFO — Set the RF_TXFIFO interrupt as active
    1=NVIC_RF_TXFIFO_INT_ACTIVE (The NVIC_RF_TXFIFO_INT_ACTIVE interrupt is active)
  [5] RF_SYNC — Set the RF_SYNC interrupt as active
    1=NVIC_RF_SYNC_INT_ACTIVE (The NVIC_RF_SYNC_INT_ACTIVE interrupt is active)
  [4] RF_RECEIVED — Set the RF_RECEIVED interrupt as active
    1=NVIC_RF_RECEIVED_INT_ACTIVE (The NVIC_RF_RECEIVED_INT_ACTIVE interrupt is active)
  [3] RF_RXSTOP — Set the RF_RXSTOP interrupt as active
    1=NVIC_RF_RXSTOP_INT_ACTIVE (The NVIC_RF_RXSTOP_INT_ACTIVE interrupt is active)
  [2] RF_TX — Set the RF_TX interrupt as active
    1=NVIC_RF_TX_INT_ACTIVE (The NVIC_RF_TX_INT_ACTIVE interrupt is active)
  [1] BLE_TOF — Set the BLE_TOF interrupt as active
    1=NVIC_BLE_TOF_INT_ACTIVE (The NVIC_BLE_TOF_INT_ACTIVE interrupt is active)
  [0] BLE_COEX_RX_TX — Set the BLE_COEX_RX_TX interrupt as active
    1=NVIC_BLE_COEX_RX_TX_INT_ACTIVE (The NVIC_BLE_COEX_RX_TX_INT_ACTIVE interrupt is active)
0x280 NVIC_ITNS0 — NVIC External Interrupt Non-secure Register 0
  [31] BLE_COEX_IN_PROCESS — Set the BLE_COEX_IN_PROCESS interrupt as non-secure
    1=NVIC_BLE_COEX_IN_PROCESS_INT_NON_SECURE (The NVIC_BLE_COEX_IN_PROCESS_INT_NON_SECURE interrupt is non-secure)
  [30] BLE_ERROR — Set the BLE_ERROR interrupt as non-secure
    1=NVIC_BLE_ERROR_INT_NON_SECURE (The NVIC_BLE_ERROR_INT_NON_SECURE interrupt is non-secure)
  [29] BLE_FIFO — Set the BLE_FIFO interrupt as non-secure
    1=NVIC_BLE_FIFO_INT_NON_SECURE (The NVIC_BLE_FIFO_INT_NON_SECURE interrupt is non-secure)
  [28] BLE_HSLOT — Set the BLE_HSLOT interrupt as non-secure
    1=NVIC_BLE_HSLOT_INT_NON_SECURE (The NVIC_BLE_HSLOT_INT_NON_SECURE interrupt is non-secure)
  [27] BLE_SLP — Set the BLE_SLP interrupt as non-secure
    1=NVIC_BLE_SLP_INT_NON_SECURE (The NVIC_BLE_SLP_INT_NON_SECURE interrupt is non-secure)
  [26] BLE_CRYPT — Set the BLE_CRYPT interrupt as non-secure
    1=NVIC_BLE_CRYPT_INT_NON_SECURE (The NVIC_BLE_CRYPT_INT_NON_SECURE interrupt is non-secure)
  [25] BLE_TIMESTAMP_TGT2 — Set the BLE_TIMESTAMP_TGT2 interrupt as non-secure
    1=NVIC_BLE_TIMESTAMP_TGT2_INT_NON_SECURE (The NVIC_BLE_TIMESTAMP_TGT2_INT_NON_SECURE interrupt is non-secure)
  [24] BLE_TIMESTAMP_TGT1 — Set the BLE_TIMESTAMP_TGT1 interrupt as non-secure
    1=NVIC_BLE_TIMESTAMP_TGT1_INT_NON_SECURE (The NVIC_BLE_TIMESTAMP_TGT1_INT_NON_SECURE interrupt is non-secure)
  [23] BLE_FINETGT — Set the BLE_FINETGT interrupt as non-secure
    1=NVIC_BLE_FINETGT_INT_NON_SECURE (The NVIC_BLE_FINETGT_INT_NON_SECURE interrupt is non-secure)
  [22] BLE_SW — Set the BLE_SW interrupt as non-secure
    1=NVIC_BLE_SW_INT_NON_SECURE (The NVIC_BLE_SW_INT_NON_SECURE interrupt is non-secure)
  [21] UART0_ERROR — Set the UART0_ERROR interrupt as non-secure
    1=NVIC_UART0_ERROR_INT_NON_SECURE (The NVIC_UART0_ERROR_INT_NON_SECURE interrupt is non-secure)
  [20] UART0_TX — Set the UART0_TX interrupt as non-secure
    1=NVIC_UART0_TX_INT_NON_SECURE (The NVIC_UART0_TX_INT_NON_SECURE interrupt is non-secure)
  [19] UART0_RX — Set the UART0_RX interrupt as non-secure
    1=NVIC_UART0_RX_INT_NON_SECURE (The NVIC_UART0_RX_INT_NON_SECURE interrupt is non-secure)
  [18] I2C0 — Set the I2C0 interrupt as non-secure
    1=NVIC_I2C0_INT_NON_SECURE (The NVIC_I2C0_INT_NON_SECURE interrupt is non-secure)
  [17] SPI0_COM — Set the SPI0_COM interrupt as non-secure
    1=NVIC_SPI0_COM_INT_NON_SECURE (The NVIC_SPI0_COM_INT_NON_SECURE interrupt is non-secure)
  [16] SPI0_TX — Set the SPI0_TX interrupt as non-secure
    1=NVIC_SPI0_TX_INT_NON_SECURE (The NVIC_SPI0_TX_INT_NON_SECURE interrupt is non-secure)
  [15] SPI0_RX — Set the SPI0_RX interrupt as non-secure
    1=NVIC_SPI0_RX_INT_NON_SECURE (The NVIC_SPI0_RX_INT_NON_SECURE interrupt is non-secure)
  [14] WATCHDOG — Set the WATCHDOG interrupt as non-secure
    1=NVIC_WATCHDOG_INT_NON_SECURE (The NVIC_WATCHDOG_INT_NON_SECURE interrupt is non-secure)
  [n+10] GPIO{n} (n=0..3) — Set the GPIO{n} interrupt as non-secure
    1=NVIC_GPIO{n}_INT_NON_SECURE (The NVIC_GPIO{n}_INT_NON_SECURE interrupt is non-secure)
  [9] ADC_FIFO — Set the ADC_FIFO interrupt as non-secure
    1=NVIC_ADC_FIFO_INT_NON_SECURE (The NVIC_ADC_FIFO_INT_NON_SECURE interrupt is non-secure)
  [8] NFC — Set the NFC interrupt as non-secure
    1=NVIC_NFC_INT_NON_SECURE (The NVIC_NFC_INT_NON_SECURE interrupt is non-secure)
  [n+4] TIMER{n} (n=0..3) — Set the TIMER{n} interrupt as non-secure
    1=NVIC_TIMER{n}_INT_NON_SECURE (The NVIC_TIMER{n}_INT_NON_SECURE interrupt is non-secure)
  [3] LSAD_BATMON — Set the LSAD_BATMON interrupt as non-secure
    1=NVIC_LSAD_BATMON_INT_NON_SECURE (The NVIC_LSAD_BATMON_INT_NON_SECURE interrupt is non-secure)
  [2] RTC_CLOCK — Set the RTC_CLOCK interrupt as non-secure
    1=NVIC_RTC_CLOCK_INT_NON_SECURE (The NVIC_RTC_CLOCK_INT_NON_SECURE interrupt is non-secure)
  [1] RTC_ALARM — Set the RTC_ALARM interrupt as non-secure
    1=NVIC_RTC_ALARM_INT_NON_SECURE (The NVIC_RTC_ALARM_INT_NON_SECURE interrupt is non-secure)
  [0] WAKEUP — Set the WAKEUP interrupt as non-secure
    1=NVIC_WAKEUP_INT_NON_SECURE (The NVIC_WAKEUP_INT_NON_SECURE interrupt is non-secure)
0x284 NVIC_ITNS1 — NVIC External Interrupt Non-secure Register 1
  [20] ASCC_PERIOD — Set the ASCC_PERIOD interrupt as non-secure
    1=NVIC_ASCC_PERIOD_INT_NON_SECURE (The NVIC_ASCC_PERIOD_INT_NON_SECURE interrupt is active)
  [19] ASCC_PHASE — Set the ASCC_PHASE interrupt as non-secure
    1=NVIC_ASCC_PHASE_INT_NON_SECURE (The NVIC_ASCC_PHASE_INT_NON_SECURE interrupt is active)
  [18] CC312 — Set the CC312 interrupt as non-secure
    1=NVIC_CC312_INT_NON_SECURE (The NVIC_CC312_INT_NON_SECURE interrupt is active)
  [n+14] DMA{n} (n=0..3) — Set the DMA{n} interrupt as non-secure
    1=NVIC_DMA{n}_INT_NON_SECURE (The NVIC_DMA{n}_INT_NON_SECURE interrupt is active)
  [13] FPU — Set the FPU interrupt as non-secure
    1=NVIC_FPU_INT_NON_SECURE (The NVIC_FPU_INT_NON_SECURE interrupt is active)
  [12] ACCESS_ERROR — Set the ACCESS_ERROR interrupt as non-secure
    1=NVIC_ACCESS_ERROR_INT_NON_SECURE (The NVIC_ACCESS_ERROR_INT_NON_SECURE interrupt is active)
  [11] FLASH1_ECC — Set the FLASH1_ECC interrupt as non-secure
    1=NVIC_FLASH1_ECC_INT_NON_SECURE (The NVIC_FLASH1_ECC_INT_NON_SECURE interrupt is active)
  [10] FLASH1_COPY — Set the FLASH1_COPY interrupt as non-secure
    1=NVIC_FLASH1_COPY_INT_NON_SECURE (The NVIC_FLASH1_COPY_INT_NON_SECURE interrupt is active)
  [9] FLASH0_ECC — Set the FLASH0_ECC interrupt as non-secure
    1=NVIC_FLASH0_ECC_INT_NON_SECURE (The NVIC_FLASH0_ECC_INT_NON_SECURE interrupt is active)
  [8] FLASH0_COPY — Set the FLASH0_COPY interrupt as non-secure
    1=NVIC_FLASH0_COPY_INT_NON_SECURE (The NVIC_FLASH0_COPY_INT_NON_SECURE interrupt is active)
  [7] RF_RXFIFO — Set the RF_RXFIFO interrupt as non-secure
    1=NVIC_RF_RXFIFO_INT_NON_SECURE (The NVIC_RF_RXFIFO_INT_NON_SECURE interrupt is active)
  [6] RF_TXFIFO — Set the RF_TXFIFO interrupt as non-secure
    1=NVIC_RF_TXFIFO_INT_NON_SECURE (The NVIC_RF_TXFIFO_INT_NON_SECURE interrupt is active)
  [5] RF_SYNC — Set the RF_SYNC interrupt as non-secure
    1=NVIC_RF_SYNC_INT_NON_SECURE (The NVIC_RF_SYNC_INT_NON_SECURE interrupt is active)
  [4] RF_RECEIVED — Set the RF_RECEIVED interrupt as non-secure
    1=NVIC_RF_RECEIVED_INT_NON_SECURE (The NVIC_RF_RECEIVED_INT_NON_SECURE interrupt is active)
  [3] RF_RXSTOP — Set the RF_RXSTOP interrupt as non-secure
    1=NVIC_RF_RXSTOP_INT_NON_SECURE (The NVIC_RF_RXSTOP_INT_NON_SECURE interrupt is active)
  [2] RF_TX — Set the RF_TX interrupt as non-secure
    1=NVIC_RF_TX_INT_NON_SECURE (The NVIC_RF_TX_INT_NON_SECURE interrupt is active)
  [1] BLE_TOF — Set the BLE_TOF interrupt as non-secure
    1=NVIC_BLE_TOF_INT_NON_SECURE (The NVIC_BLE_TOF_INT_NON_SECURE interrupt is active)
  [0] BLE_COEX_RX_TX — Set the BLE_COEX_RX_TX interrupt as non-secure
    1=NVIC_BLE_COEX_RX_TX_INT_NON_SECURE (The NVIC_BLE_COEX_RX_TX_INT_NON_SECURE interrupt is active)
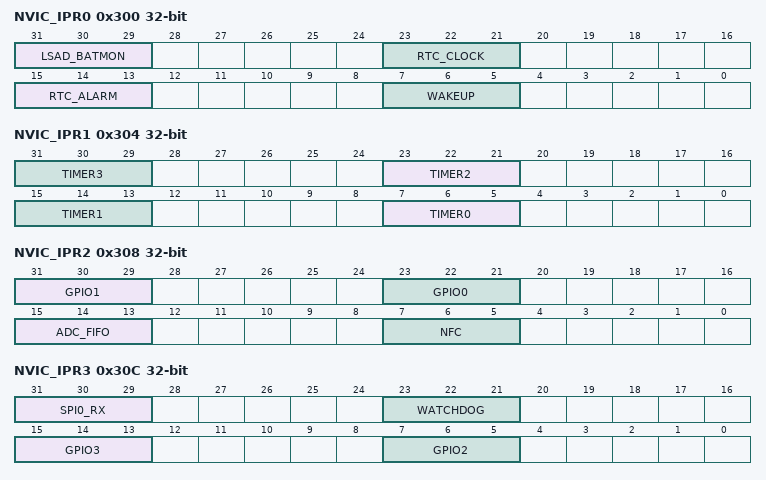
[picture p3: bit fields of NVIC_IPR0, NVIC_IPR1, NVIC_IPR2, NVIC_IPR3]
0x300 NVIC_IPR0 — NVIC External Interrupt Priority Register 0
  [31:29] LSAD_BATMON — Configure the LSAD_BATMON interrupt priority
  [23:21] RTC_CLOCK — Configure the RTC_CLOCK interrupt priority
  [15:13] RTC_ALARM — Configure the RTC_ALARM interrupt priority
  [7:5] WAKEUP — Configure the WAKEUP interrupt priority
0x304 NVIC_IPR1 — NVIC External Interrupt Priority Register 1
  [8n+7:8n+5] TIMER{n} (n=0..3) — Configure the TIMER{n} interrupt priority
0x308 NVIC_IPR2 — NVIC External Interrupt Priority Register 2
  [31:29] GPIO1 — Configure the GPIO1 interrupt priority
  [23:21] GPIO0 — Configure the GPIO0 interrupt priority
  [15:13] ADC_FIFO — Configure the ADC_FIFO interrupt priority
  [7:5] NFC — Configure the NFC interrupt priority
0x30C NVIC_IPR3 — NVIC External Interrupt Priority Register 3
  [31:29] SPI0_RX — Configure the SPI0_RX interrupt priority
  [23:21] WATCHDOG — Configure the WATCHDOG interrupt priority
  [15:13] GPIO3 — Configure the GPIO3 interrupt priority
  [7:5] GPIO2 — Configure the GPIO2 interrupt priority
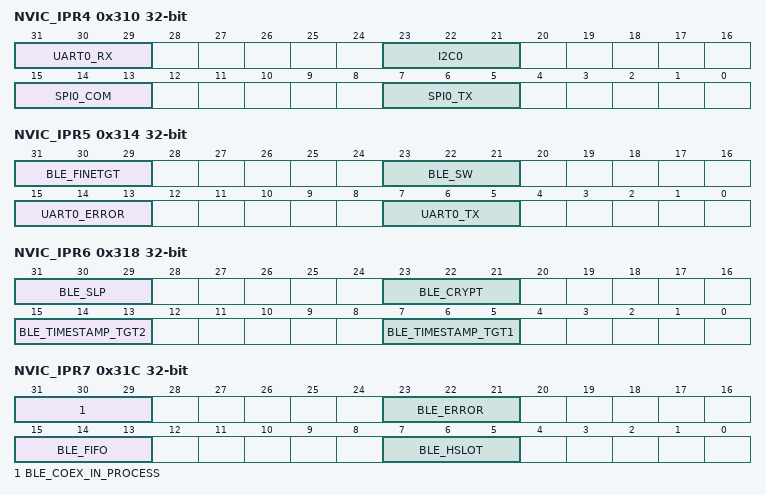
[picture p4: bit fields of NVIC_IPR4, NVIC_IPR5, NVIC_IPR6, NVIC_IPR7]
0x310 NVIC_IPR4 — NVIC External Interrupt Priority Register 4
  [31:29] UART0_RX — Configure the UART0_RX interrupt priority
  [23:21] I2C0 — Configure the I2C0 interrupt priority
  [15:13] SPI0_COM — Configure the SPI0_COM interrupt priority
  [7:5] SPI0_TX — Configure the SPI0_TX interrupt priority
0x314 NVIC_IPR5 — NVIC External Interrupt Priority Register 5
  [31:29] BLE_FINETGT — Configure the BLE_FINETGT interrupt priority
  [23:21] BLE_SW — Configure the BLE_SW interrupt priority
  [15:13] UART0_ERROR — Configure the UART0_ERROR interrupt priority
  [7:5] UART0_TX — Configure the UART0_TX interrupt priority
0x318 NVIC_IPR6 — NVIC External Interrupt Priority Register 6
  [31:29] BLE_SLP — Configure the BLE_SLP interrupt priority
  [23:21] BLE_CRYPT — Configure the BLE_CRYPT interrupt priority
  [15:13] BLE_TIMESTAMP_TGT2 — Configure the BLE_TIMESTAMP_TGT2 interrupt priority
  [7:5] BLE_TIMESTAMP_TGT1 — Configure the BLE_TIMESTAMP_TGT1 interrupt priority
0x31C NVIC_IPR7 — NVIC External Interrupt Priority Register 7
  [31:29] BLE_COEX_IN_PROCESS — Configure the BLE_COEX_IN_PROCESS interrupt priority
  [23:21] BLE_ERROR — Configure the BLE_ERROR interrupt priority
  [15:13] BLE_FIFO — Configure the BLE_FIFO interrupt priority
  [7:5] BLE_HSLOT — Configure the BLE_HSLOT interrupt priority
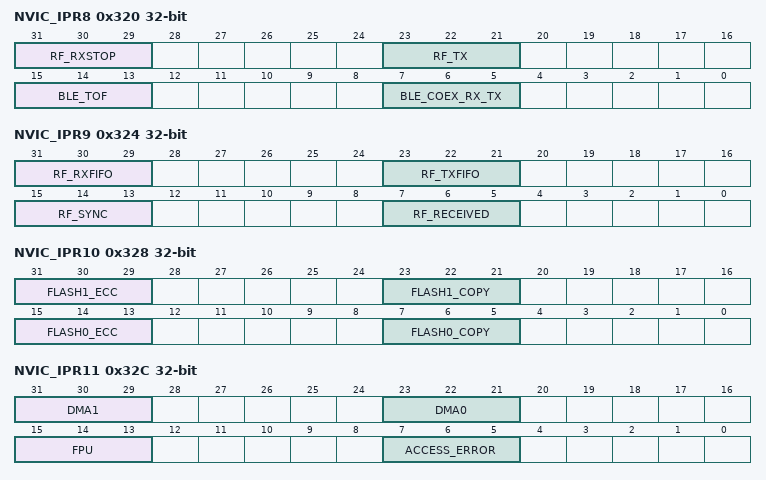
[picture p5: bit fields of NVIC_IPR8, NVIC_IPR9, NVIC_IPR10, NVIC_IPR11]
0x320 NVIC_IPR8 — NVIC External Interrupt Priority Register 8
  [31:29] RF_RXSTOP — Configure the RF_RXSTOP interrupt priority
  [23:21] RF_TX — Configure the RF_TX interrupt priority
  [15:13] BLE_TOF — Configure the BLE_TOF interrupt priority
  [7:5] BLE_COEX_RX_TX — Configure the BLE_COEX_RX_TX interrupt priority
0x324 NVIC_IPR9 — NVIC External Interrupt Priority Register 9
  [31:29] RF_RXFIFO — Configure the RF_RXFIFO interrupt priority
  [23:21] RF_TXFIFO — Configure the RF_TXFIFO interrupt priority
  [15:13] RF_SYNC — Configure the RF_SYNC interrupt priority
  [7:5] RF_RECEIVED — Configure the RF_RECEIVED interrupt priority
0x328 NVIC_IPR10 — NVIC External Interrupt Priority Register 10
  [31:29] FLASH1_ECC — Configure the FLASH1_ECC interrupt priority
  [23:21] FLASH1_COPY — Configure the FLASH1_COPY interrupt priority
  [15:13] FLASH0_ECC — Configure the FLASH0_ECC interrupt priority
  [7:5] FLASH0_COPY — Configure the FLASH0_COPY interrupt priority
0x32C NVIC_IPR11 — NVIC External Interrupt Priority Register 11
  [31:29] DMA1 — Configure the DMA1 interrupt priority
  [23:21] DMA0 — Configure the DMA0 interrupt priority
  [15:13] FPU — Configure the FPU interrupt priority
  [7:5] ACCESS_ERROR — Configure the ACCESS_ERROR interrupt priority
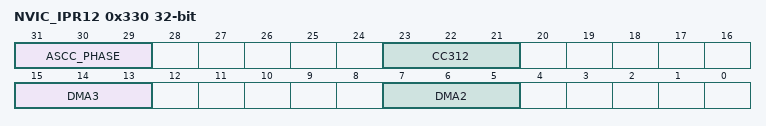
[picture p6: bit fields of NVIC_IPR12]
0x330 NVIC_IPR12 — NVIC External Interrupt Priority Register 12
  [31:29] ASCC_PHASE — Configure the ASCC_PHASE interrupt priority
  [23:21] CC312 — Configure the CC312 interrupt priority
  [15:13] DMA3 — Configure the DMA3 interrupt priority
  [7:5] DMA2 — Configure the DMA2 interrupt priority
0x334 NVIC_IPR13 — NVIC External Interrupt Priority Register 13
  [7:5] ASCC_PERIOD — Configure the ASCC_PERIOD interrupt priority
0x20000 NVIC_ISER0_NS access not given reset not defined — NVIC External Interrupt Set Enable Register 0
0x20004 NVIC_ISER1_NS access not given reset not defined — NVIC External Interrupt Set Enable Register 1
0x20080 NVIC_ICER0_NS access not given reset not defined — NVIC External Interrupt Clear Enable Register 0
0x20084 NVIC_ICER1_NS access not given reset not defined — NVIC External Interrupt Clear Enable Register 1
0x20100 NVIC_ISPR0_NS access not given reset not defined — NVIC External Interrupt Set Pending Register 0
0x20104 NVIC_ISPR1_NS access not given reset not defined — NVIC External Interrupt Set Pending Register 1
0x20180 NVIC_ICPR0_NS access not given reset not defined — NVIC External Interrupt Clear Pending Register 0
0x20184 NVIC_ICPR1_NS access not given reset not defined — NVIC External Interrupt Clear Pending Register 1
0x20200 NVIC_IABR0_NS access not given reset not defined — NVIC External Interrupt Active Register 0
0x20204 NVIC_IABR1_NS access not given reset not defined — NVIC External Interrupt Active Register 1
{0x20300+4i} NVIC_IPR{i}_NS access not given reset not defined (i=0..13) — NVIC External Interrupt Priority Register {i}
